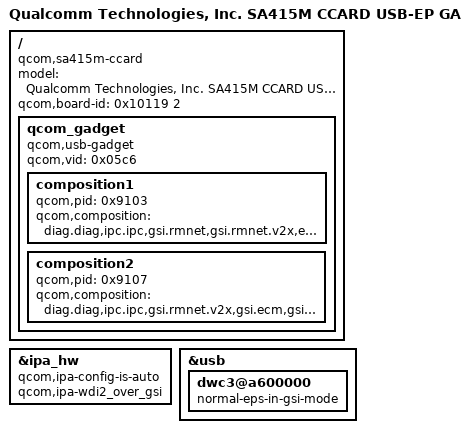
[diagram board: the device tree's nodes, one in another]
/dts-v1/;

#include "sa415m-ccard.dtsi"

/ {
	model = "Qualcomm Technologies, Inc. SA415M CCARD USB-EP GA";
	compatible = "qcom,sa415m-ccard",
			"qcom,sa415m", "qcom,ccard";
	qcom,board-id = <0x10119 2>;

	qcom_gadget {
		compatible = "qcom,usb-gadget";
		qcom,vid = <0x05c6>;

		composition1 {
			qcom,pid = <0x9103>;
			qcom,composition = "diag.diag,ipc.ipc,gsi.rmnet,gsi.rmnet.v2x,ecm.ecm,gsi.dpl";
		};

		composition2 {
			qcom,pid = <0x9107>;
			qcom,composition = "diag.diag,ipc.ipc,gsi.rmnet.v2x,gsi.ecm,gsi.dpl";
		};
	};

};

&ipa_hw {
	qcom,ipa-config-is-auto;
	qcom,ipa-wdi2_over_gsi;
};

&usb {
	dwc3@a600000 {
		normal-eps-in-gsi-mode;
	};
};
